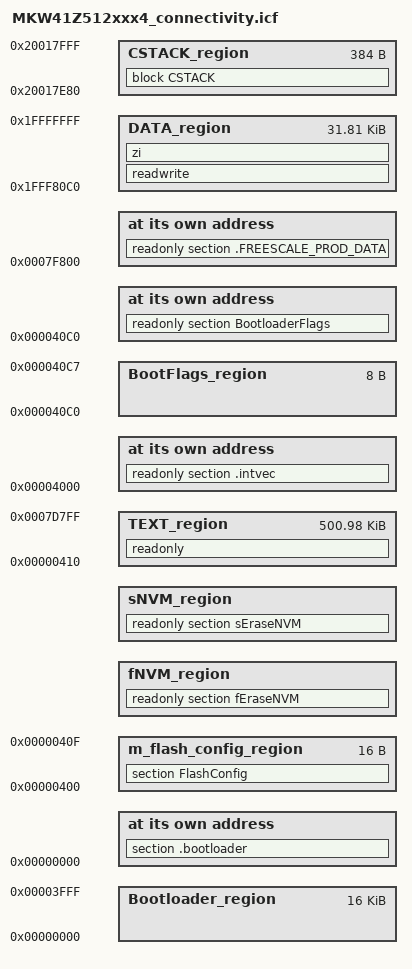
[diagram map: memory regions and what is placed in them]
/*
** ###################################################################
**     Processor:           MKW41Z512VHT4
**     Compiler:            IAR ANSI C/C++ Compiler for ARM
**     Reference manual:    MKW40Z160VHT4RM Rev 0.2, 7/2014
**     Version:             rev. 1.0, 2014-07-17
**     Build:               b140915
**
**     Abstract:
**         Linker file for the IAR ANSI C/C++ Compiler for ARM
**
**     The Clear BSD License
**     Copyright (c) 2015, Freescale Semiconductor, Inc.
**     Copyright 2016-2017 NXP
**     All rights reserved.
*
**     Redistribution and use in source and binary forms, with or without
**     modification, are permitted (subject to the limitations in the
**     disclaimer below) provided that the following conditions are met:
**     
**     * Redistributions of source code must retain the above copyright
**       notice, this list of conditions and the following disclaimer.
**     
**     * Redistributions in binary form must reproduce the above copyright
**       notice, this list of conditions and the following disclaimer in the
**       documentation and/or other materials provided with the distribution.
**     
**     * Neither the name of the copyright holder nor the names of its
**       contributors may be used to endorse or promote products derived from
**       this software without specific prior written permission.
**     
**     NO EXPRESS OR IMPLIED LICENSES TO ANY PARTY'S PATENT RIGHTS ARE
**     GRANTED BY THIS LICENSE. THIS SOFTWARE IS PROVIDED BY THE COPYRIGHT
**     HOLDERS AND CONTRIBUTORS "AS IS" AND ANY EXPRESS OR IMPLIED
**     WARRANTIES, INCLUDING, BUT NOT LIMITED TO, THE IMPLIED WARRANTIES OF
**     MERCHANTABILITY AND FITNESS FOR A PARTICULAR PURPOSE ARE
**     DISCLAIMED. IN NO EVENT SHALL THE COPYRIGHT HOLDER OR CONTRIBUTORS BE
**     LIABLE FOR ANY DIRECT, INDIRECT, INCIDENTAL, SPECIAL, EXEMPLARY, OR
**     CONSEQUENTIAL DAMAGES (INCLUDING, BUT NOT LIMITED TO, PROCUREMENT OF
**     SUBSTITUTE GOODS OR SERVICES; LOSS OF USE, DATA, OR PROFITS; OR
**     BUSINESS INTERRUPTION) HOWEVER CAUSED AND ON ANY THEORY OF LIABILITY,
**     WHETHER IN CONTRACT, STRICT LIABILITY, OR TORT (INCLUDING NEGLIGENCE
**     OR OTHERWISE) ARISING IN ANY WAY OUT OF THE USE OF THIS SOFTWARE, EVEN
**     IF ADVISED OF THE POSSIBILITY OF SUCH DAMAGE.
**
** ###################################################################
*/

/*  */
if (!isdefinedsymbol(_flash_start)) {
  define exported symbol _flash_start = 0;
}

if (!isdefinedsymbol(_FlsLinkKey)) {
  define exported symbol _FlsLinkKey = 0;
}

if (!isdefinedsymbol(_FlsOtaHeader)) {
  define exported symbol _FlsOtaHeader = 0;
}


if (!isdefinedsymbol(u16ImageStartSector)) {
  define exported symbol u16ImageStartSector = 0;
}

if (!isdefinedsymbol(_enc_start)) {
  define exported symbol _enc_start = 0;
}


/* By default, the Bootloader is not used. */
if (!isdefinedsymbol(gUseBootloaderLink_d)) {
  define symbol gUseBootloaderLink_d = 0;
}

/* By default, the NVM is not used. */
if (!isdefinedsymbol(gUseNVMLink_d)) {
  define symbol gUseNVMLink_d = 0;
}

if (!isdefinedsymbol(gEraseNVMLink_d)) {
  define symbol gEraseNVMLink_d = 0;
}

if (!isdefinedsymbol(gNVMSectorCountLink_d)) {
  define symbol gNVMSectorCountLink_d = 4;
}

/* By default, the internal storage is not used. */
if (!isdefinedsymbol(gUseInternalStorageLink_d)) {
  define symbol gUseInternalStorageLink_d = 0;
}

/* By default, the RAM vector table is used. */
if (!isdefinedsymbol(__ram_vector_table__))
{
  define symbol __ram_vector_table__ = 1;
}


/*-Memory Limits-*/
define symbol __region_ROM_start__   = 0x00000000 ;
define symbol __region_ROM_end__     = 0x0007FFFF;
define symbol __region_RAM_start__   = 0x1FFF8000;
define symbol __region_RAM_end__     = 0x20017FFF;

define symbol __vector_table_size__    =   48*4;

if(__ram_vector_table__)
{
  define symbol __ram_vector_table_size__ = __vector_table_size__;
}
else
{
  define symbol __ram_vector_table_size__ = 0;
}

define exported symbol _RAM_START_  = __region_RAM_start__;
define exported symbol _RAM_END_    = __region_RAM_end__;

if (gUseBootloaderLink_d) 
{
  define symbol m_bootloader_start       = __region_ROM_start__;
  define symbol m_bootloader_end         = ((__region_ROM_end__ + 1) / 32) - 1;

  define symbol m_interrupts_start       = m_bootloader_end + 1;
  define symbol m_interrupts_end         = m_interrupts_start + __vector_table_size__ - 1;

  define symbol m_bootFlags_start        = m_interrupts_end + 1;
  define symbol m_bootFlags_end          = m_bootFlags_start + 7;

  define exported symbol __BootFlags_Start__ = m_bootFlags_start;
}
else
{
  define symbol m_interrupts_start       = __region_ROM_start__;
  define symbol m_interrupts_end         = m_interrupts_start + __vector_table_size__ - 1;
  define symbol m_flash_config_start     = 0x00000400;
  define symbol m_flash_config_end       = 0x0000040F;
}


/*-Sizes-*/
define symbol m_sector_size             = 2*1024; /* 2k flash sector size */

if (isdefinedsymbol(__stack_size__)) {
  define symbol __size_cstack__        = __stack_size__;
} else {
  define symbol __size_cstack__        = 384;
}

if (isdefinedsymbol(__heap_size__)) {
  define symbol __size_heap__          = __heap_size__;
} else {
  define symbol __size_heap__          = 0;
}


/*** FSL Product Info region ***/
define symbol m_fsl_prodInfo_start     = __region_ROM_end__ - m_sector_size + 1;
define symbol m_fsl_prodInfo_end       = __region_ROM_end__;
define exported symbol FREESCALE_PROD_DATA_BASE_ADDR = m_fsl_prodInfo_start;


/*** NVM Configuration ***/
if( gUseNVMLink_d )
{
  define exported symbol NV_STORAGE_SECTOR_SIZE = m_sector_size;
  define exported symbol NV_STORAGE_MAX_SECTORS = gNVMSectorCountLink_d;     /* NV_STORAGE_MAX_SECTORS * NV_STORAGE_SECTOR_SIZE = total NV Storage space */

  if (!isdefinedsymbol(NV_STORAGE_START_ADDRESS)) {
    define exported symbol NV_STORAGE_START_ADDRESS = m_fsl_prodInfo_start - 1;
  }

  define exported symbol NV_STORAGE_END_ADDRESS = NV_STORAGE_START_ADDRESS - (NV_STORAGE_MAX_SECTORS * NV_STORAGE_SECTOR_SIZE) + 1;
}

if (gUseInternalStorageLink_d) 
{
  if( gUseNVMLink_d )
  {
    define exported symbol INT_STORAGE_START = NV_STORAGE_END_ADDRESS - 1;
  }
  else
  {
    define exported symbol INT_STORAGE_START = m_fsl_prodInfo_start - 1;
  }
  define exported symbol INT_STORAGE_SIZE  = m_sector_size * ( ((INT_STORAGE_START + 1 - __region_ROM_start__)/2)/m_sector_size +1);
  define exported symbol INT_STORAGE_END   = INT_STORAGE_START - INT_STORAGE_SIZE + 1;
  define exported symbol INT_STORAGE_SECTOR_SIZE = m_sector_size;
}


/* Define the limits of the memory regions*/
define symbol m_text_start             = m_interrupts_start;
if( gUseInternalStorageLink_d )
{
  define symbol m_text_end               = INT_STORAGE_END;
}
else if( gUseNVMLink_d )
{
  define symbol m_text_end               = NV_STORAGE_END_ADDRESS - 1;
}
else
{
  define symbol m_text_end               = m_fsl_prodInfo_start - 1;
}

define symbol m_interrupts_ram_start   = __region_RAM_start__;
define symbol m_interrupts_ram_end     = m_interrupts_ram_start + __ram_vector_table_size__ - 1;

define symbol __CSTACK_end__   = __region_RAM_end__;
define symbol __CSTACK_start__ = __CSTACK_end__ - __size_cstack__ + 1;
define symbol __HEAP_end__     = __CSTACK_start__ - 1;
define symbol __HEAP_start__   = __HEAP_end__ - __size_heap__ + 1;

define symbol m_data_start             = m_interrupts_ram_end + 1;
define symbol m_data_end               = __HEAP_start__ - 1;


define exported symbol __VECTOR_TABLE  = m_interrupts_start;
define exported symbol __VECTOR_RAM    = isdefinedsymbol(__ram_vector_table__) ? m_interrupts_ram_start : m_interrupts_start;
define exported symbol __RAM_VECTOR_TABLE_SIZE = __ram_vector_table_size__;
define exported symbol __BOOT_STACK_ADDRESS = m_data_end-0x0F;


/*** Define memory regions ***/
define memory mem with size = 4G;
if (gUseBootloaderLink_d)
{
  define region Bootloader_region = mem:[from m_bootloader_start  to  m_bootloader_end];
  define region BootFlags_region  = mem:[from m_bootFlags_start   to  m_bootFlags_end];
  define region TEXT_region       = mem:[from m_text_start to m_bootFlags_start-1] |
                                    mem:[from m_bootFlags_end+1 to m_text_end];
}
else
{
  define region m_flash_config_region = mem:[from m_flash_config_start to m_flash_config_end];
  define region TEXT_region = mem:[from m_text_start to m_flash_config_start - 1] |
                              mem:[from m_flash_config_end + 1 to m_text_end];
}

if (gUseInternalStorageLink_d) {
  define region InternalStorage    = mem:[from INT_STORAGE_END to INT_STORAGE_START];
}

if(gUseNVMLink_d) {
  define symbol NV_VIRTUAL_PAGE_BOUND = NV_STORAGE_START_ADDRESS - (NV_STORAGE_MAX_SECTORS/2 * NV_STORAGE_SECTOR_SIZE);
  define region fNVM_region         = mem:[from  NV_VIRTUAL_PAGE_BOUND+1 to NV_STORAGE_START_ADDRESS];
  define region sNVM_region         = mem:[from  NV_STORAGE_END_ADDRESS to NV_VIRTUAL_PAGE_BOUND];
  if(gEraseNVMLink_d)
  {
	 place in fNVM_region              {readonly section fEraseNVM };
	 place in sNVM_region              {readonly section sEraseNVM };
  } 
}

define region DATA_region   = mem:[from m_data_start to 0x1FFFFFFF] | [from 0x20000000 to m_data_end];
define region HEAP_region   = mem:[from __HEAP_start__ to __HEAP_end__];
define region CSTACK_region = mem:[from __CSTACK_start__ to __CSTACK_end__];

define block CSTACK    with alignment = 8, size = __size_cstack__   { };
define block HEAP      with alignment = 8, size = __size_heap__     { };

initialize by copy { readwrite, section .textrw };
do not initialize  { section .noinit };


/*** Memory placements ***/
place at address mem: m_interrupts_start    { readonly section .intvec };
place at address mem: m_fsl_prodInfo_start  { readonly section .FREESCALE_PROD_DATA };
place in TEXT_region                        { readonly };
place in DATA_region                        { readwrite, zi };
place in HEAP_region                        { block HEAP };
place in CSTACK_region                      { block CSTACK };


if (gUseBootloaderLink_d) 
{
  place at address mem: m_bootloader_start  { section .bootloader };
  place at address mem: m_bootFlags_start   { readonly section BootloaderFlags };
}
else
{
  place in m_flash_config_region              { section FlashConfig };
}

